# ADSP-2183xW_LPC register map
Vendor: Analog Devices; Series: ADSP-2183xW_LPC; File version: 3.0.3.517
CPU: 
Registers are 32-bit, read-write, reset 0x0 unless marked. A register's access mark holds for its fields unless they carry their own. Offsets are from the block's base; [hi:lo] are bit positions; {n}, {i} and the like mark numbered series.

## SPI1 — Serial Peripheral Interface
Base 0x3102F000
Same registers: SPI2 0x31030000
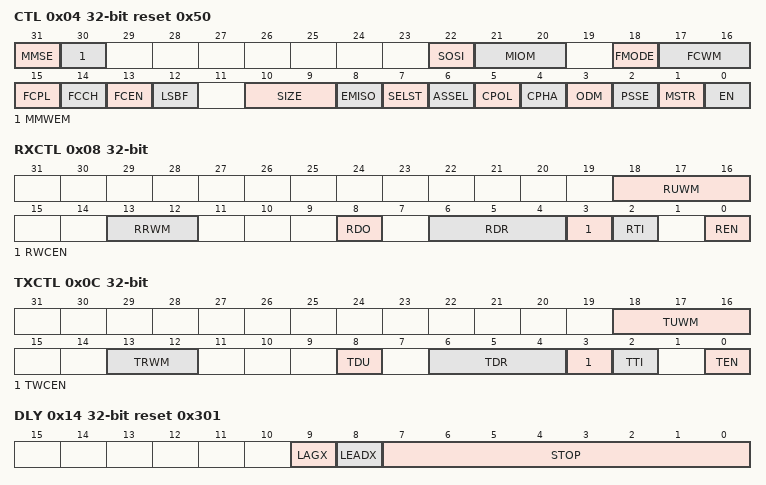
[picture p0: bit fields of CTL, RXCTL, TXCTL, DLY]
0x04 CTL reset 0x50 — Control Register
  [31] MMSE — Memory-Mapped SPI Enable
    0=MM_DIS (Hardware automated access of memory-mapped SPI memory disabled.); 1=MM_EN (Hardware-automated access of memory-mapped SPI memory enabled.)
  [30] MMWEM — Memory Mapped Write Error Mask
    0=WEM_UNMSK (Write error response returned upon write attempts to memory-mapped SPI memory); 1=WEM_MSK (Write error response masked (not returned) upon write attempts to memory-mapped SPI memory)
  [22] SOSI — Start on MOSI
    0=STMISO (Start on MISO (DIOM) or start on SPI_D3); 1=STMOSI (Start on MOSI)
  [21:20] MIOM — Multiple I/O Mode
    0=MIO_DIS (No MIOM (disabled)); 1=MIO_DUAL (DIOM operation); 2=MIO_QUAD (QIOM operation)
  [18] FMODE — Fast-Mode Enable
    0=FAST_DIS (Disable); 1=FAST_EN (Enable)
  [17:16] FCWM — Flow Control Watermark
    0=FIFO0 (TFIFO empty or RFIFO full); 1=FIFO1 (TFIFO 75 percent or more empty, or RFIFO 75 percent or more full); 2=FIFO2 (TFIFO 50 percent or more empty, or RFIFO 50 percent or more full)
  [15] FCPL — Flow Control Polarity
    0=FLOW_LO (Active-low RDY); 1=FLOW_HI (Active-high RDY)
  [14] FCCH — Flow Control Channel Selection
    0=FLOW_RX (Flow control on RX buffer); 1=FLOW_TX (Flow control on TX buffer)
  [13] FCEN — Flow Control Enable
    0=FLOW_DIS (Disable); 1=FLOW_EN (Enable)
  [12] LSBF — Least Significant Bit First
    0=MSB_FIRST (MSB sent/received first (big endian)); 1=LSB_FIRST (LSB sent/received first (little endian))
  [10:9] SIZE — Word Transfer Size
    0=8-bit word; 1=16-bit word; 2=32-bit word
  [8] EMISO — Enable MISO
    0=MISO_DIS (Disable); 1=MISO_EN (Enable)
  [7] SELST — Slave Select Polarity Between Transfers
    0=DEASSRT_SSEL (Deassert slave select (high)); 1=ASSRT_SSEL (Assert slave select (low))
  [6] ASSEL — Slave Select Pin Control
    0=SW_SSEL (Software slave select control); 1=HW_SSEL (Hardware slave select control)
  [5] CPOL — Clock Polarity
    0=SCKHI (Active-high SPI CLK); 1=SCKLO (Active-low SPI CLK)
  [4] CPHA — Clock Phase
    0=SCKMID (SPI CLK toggles from middle); 1=SCKBEG (SPI CLK toggles from start)
  [3] ODM — Open Drain Mode
    0=ODM_DIS (Disable); 1=ODM_EN (Enable)
  [2] PSSE — Protected Slave Select Enable
    0=PSSE_DIS (Disable); 1=PSSE_EN (Enable)
  [1] MSTR — Master/Slave
    0=SLAVE; 1=MASTER
  [0] EN — Enable
    0=DIS (Disable SPI module); 1=EN (Enable)
0x08 RXCTL — Receive Control Register
  [18:16] RUWM — Receive FIFO Urgent Watermark
    0=UWM_DIS (Disabled); 1=UWM_25 (25 percent full RFIFO); 2=UWM_50 (50 percent full RFIFO); 3=UWM_75 (75 percent full RFIFO); 4=UWM_FULL (Full RFIFO)
  [13:12] RRWM — Receive FIFO Regular Watermark
    0=RWM_0 (Empty RFIFO); 1=RWM_25 (RFIFO less than 25 percent full); 2=RWM_50 (RFIFO less than 50 percent full); 3=RWM_75 (RFIFO less than 75 percent full)
  [8] RDO — Receive Data Overrun
    0=DISCARD (Discard incoming data if SPI_RFIFO is full); 1=OVERWRITE (Overwrite old data if SPI_RFIFO is full)
  [6:4] RDR — Receive Data Request
    0=RDR_DIS (Disabled); 1=RDR_NE (Not empty RFIFO); 2=25 percent full RFIFO; 3=50 percent full RFIFO; 4=75 percent full RFIFO; 5=RDR_FULL (Full RFIFO)
  [3] RWCEN — Receive Word Counter Enable
    0=RWC_DIS (Disable); 1=RWC_EN (Enable)
  [2] RTI — Receive Transfer Initiate
    0=RTI_DIS (Disable); 1=RTI_EN (Enable)
  [0] REN — Receive Enable
    0=RX_DIS (Disable); 1=RX_EN (Enable)
0x0C TXCTL — Transmit Control Register
  [18:16] TUWM — FIFO Urgent Watermark
    0=UWM_DIS (Disabled); 1=UWM_25 (25 percent empty TFIFO); 2=UWM_50 (50 percent empty TFIFO); 3=UWM_75 (75 percent empty TFIFO); 4=UWM_EMPTY (Empty TFIFO)
  [13:12] TRWM — FIFO Regular Watermark
    0=RWM_FULL (Full TFIFO); 1=RWM_25 (TFIFO less than 25 percent empty); 2=RWM_50 (TFIFO less than 50 percent empty); 3=RWM_75 (TFIFO less than 75 percent empty)
  [8] TDU — Transmit Data Underrun
    0=LASTWD (Send last word when SPI_TFIFO is empty); 1=ZERO (Send zeros when SPI_TFIFO is empty)
  [6:4] TDR — Transmit Data Request
    0=TDR_DIS (Disabled); 1=TDR_NF (Not full TFIFO); 2=25 percent empty TFIFO; 3=50 percent empty TFIFO; 4=75 percent empty TFIFO; 5=TDR_EMPTY (Empty TFIFO)
  [3] TWCEN — Transmit Word Counter Enable
    0=TWC_DIS (Disable); 1=TWC_EN (Enable)
  [2] TTI — Transmit Transfer Initiate
    0=TTI_DIS (Disable); 1=TTI_EN (Enable)
  [0] TEN — Transmit Enable
    0=TX_DIS (Disable); 1=TX_EN (Enable)
0x10 CLK — Clock Rate Register
  [15:0] BAUD range 0x00000000..0x0000FFFF — Baud Rate
0x14 DLY reset 0x301 — Delay Register
  [9] LAGX — Extended SPI Clock Lag Control
  [8] LEADX — Extended SPI Clock Lead Control
  [7:0] STOP range 0x00000000..0x000000FF — Transfer Delay Time in Multiples of SPI Clock Period
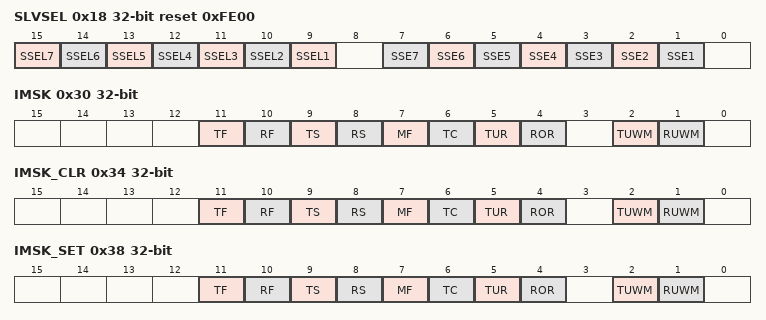
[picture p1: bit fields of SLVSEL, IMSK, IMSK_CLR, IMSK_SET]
0x18 SLVSEL reset 0xFE00 — Slave Select Register
  [n+8] SSEL{n} (n=1..7) — Slave Select {n} Output
    0=SSEL{n}_LO (Low); 1=SSEL{n}_HI (High)
  [n] SSE{n} (n=1..7) — Slave Select {n} Enable
    0=SSEL{n}_DIS (Disable); 1=SSEL{n}_EN (Enable)
0x1C RWC — Received Word Count Register
  [15:0] VALUE range 0x00000000..0x0000FFFF — Received Word Count
0x20 RWCR — Received Word Count Reload Register
  [15:0] VALUE range 0x00000000..0x0000FFFF — Received Word Count Reload
0x24 TWC — Transmitted Word Count Register
  [15:0] VALUE range 0x00000000..0x0000FFFF — Transmitted Word Count
0x28 TWCR — Transmitted Word Count Reload Register
  [15:0] VALUE range 0x00000000..0x0000FFFF — Transmitted Word Count Reload
0x30 IMSK — Interrupt Mask Register
  [11] TF ro — Transmit Finish
    0=TF_LO (Disable (mask) interrupt request); 1=TF_HI (Enable (unmask) interrupt request)
  [10] RF ro — Receive Finish
    0=RF_LO (Disable (mask) interrupt request); 1=RF_HI (Enable (unmask) interrupt request)
  [9] TS ro — Transmit Start
    0=TS_LO (Disable (mask) interrupt request); 1=TS_HI (Enable (unmask) interrupt request)
  [8] RS ro — Receive Start
    0=RS_LO (Disable (mask) interrupt request); 1=RS_HI (Enable (unmask) interrupt request)
  [7] MF ro — Mode Fault
    0=MF_LO (Disable (mask) interrupt request); 1=MF_HI (Enable (unmask) interrupt request)
  [6] TC ro — Transmit Collision
    0=TC_LO (Disable (mask) interrupt request); 1=TC_HI (Enable (unmask) interrupt request)
  [5] TUR ro — Transmit Underrun
    0=TUR_LO (Disable (mask) interrupt request); 1=TUR_HI (Enable (unmask) interrupt request)
  [4] ROR ro — Receive Overrun
    0=ROR_LO (Disable (mask) interrupt request); 1=ROR_HI (Enable (unmask) interrupt request)
  [2] TUWM ro — Transmit Urgent Watermark
    0=TUWM_LO (Disable (mask) interrupt request); 1=TUWM_HI (Enable (unmask) interrupt request)
  [1] RUWM ro — Receive Urgent Watermark
    0=RUWM_LO (Disable (mask) interrupt request); 1=RUWM_HI (Enable (unmask) interrupt request)
0x34 IMSK_CLR — Interrupt Mask Clear Register
  [11] TF — Clear Transmit Finish
  [10] RF — Clear Receive Finish
  [9] TS — Clear Transmit Start
  [8] RS — Clear Receive Start
  [7] MF — Clear Mode Fault
  [6] TC — Clear Transmit Collision
  [5] TUR — Clear Transmit Underrun
  [4] ROR — Clear Receive Overrun
  [2] TUWM — Clear Transmit Urgent Watermark
  [1] RUWM — Clear Receive Urgent Watermark
0x38 IMSK_SET — Interrupt Mask Set Register
  [11] TF — Set Transmit Finish
  [10] RF — Set Receive Finish
  [9] TS — Set Transmit Start
  [8] RS — Set Receive Start
  [7] MF — Set Mode Fault
  [6] TC — Set Transmit Collision
  [5] TUR — Set Transmit Underrun
  [4] ROR — Set Receive Overrun
  [2] TUWM — Set Transmit Urgent Watermark
  [1] RUWM — Set Receive Urgent Watermark
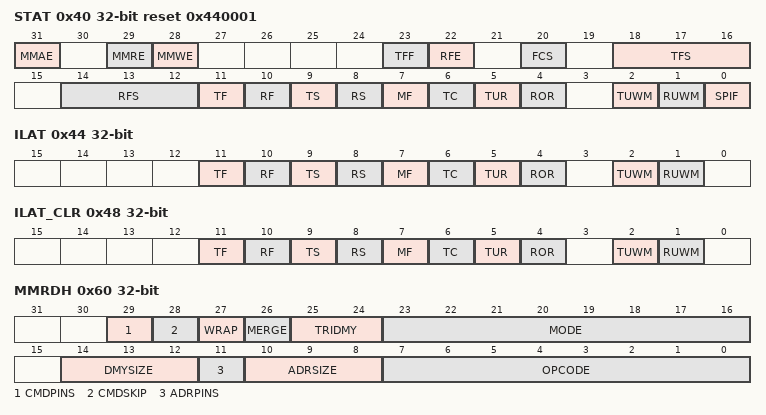
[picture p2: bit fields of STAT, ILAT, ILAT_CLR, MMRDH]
0x40 STAT reset 0x440001 — Status Register
  [31] MMAE range 0x00000000..0x00000001 — Memory Mapped Access Error
  [29] MMRE range 0x00000000..0x00000001 — Memory Mapped Read Error
  [28] MMWE range 0x00000000..0x00000001 — Memory Mapped Write Error
  [23] TFF ro — SPI_TFIFO Full
    0=TFIFO_NF (Not full Tx FIFO); 1=TFIFO_F (Full Tx FIFO)
  [22] RFE ro — SPI_RFIFO Empty
    0=RFIFO_NE (Rx FIFO not empty); 1=RFIFO_E (Rx FIFO empty)
  [20] FCS ro — Flow Control Stall Indication
    0=STALL (No Stall (RDY pin asserted)); 1=NOSTALL (Stall (RDY pin deasserted))
  [18:16] TFS ro — SPI_TFIFO Status
    0=TFIFO_FULL (Full TFIFO); 1=TFIFO_25 (25 percent empty TFIFO); 2=TFIFO_50 (50 percent empty TFIFO); 3=TFIFO_75 (75 percent empty TFIFO); 4=TFIFO_EMPTY (Empty TFIFO)
  [14:12] RFS ro — SPI_RFIFO Status
    0=RFIFO_EMPTY (Empty RFIFO); 1=RFIFO_25 (25 percent full RFIFO); 2=RFIFO_50 (50 percent full RFIFO); 3=RFIFO_75 (75 percent full RFIFO); 4=RFIFO_FULL (Full RFIFO)
  [11] TF — Transmit Finish Indication
    0=TF_LO (No status); 1=TF_HI (Transmit finish detected)
  [10] RF — Receive Finish Indication
    0=RF_LO (No status); 1=RF_HI (Receive finish detected)
  [9] TS — Transmit Start
    0=TS_LO (No status); 1=TS_HI (Transmit start detected)
  [8] RS — Receive Start
    0=RS_LO (No status); 1=RS_HI (Receive start detected)
  [7] MF — Mode Fault Indication
    0=MF_LO (No status); 1=MF_HI (Mode fault occurred)
  [6] TC — Transmit Collision Indication
    0=TC_LO (No status); 1=TC_HI (Transmit collision occurred)
  [5] TUR — Transmit Underrun Indication
    0=TUR_LO (No status); 1=TUR_HI (Transmit underrun occurred)
  [4] ROR — Receive Overrun Indication
    0=ROR_LO (No status); 1=ROR_HI (Receive overrun occurred)
  [2] TUWM ro — Transmit Urgent Watermark Breached
    0=TUWM_LO (Tx regular watermark reached); 1=TUWM_HI (Tx urgent watermark breached)
  [1] RUWM ro — Receive Urgent Watermark Breached
    0=RUWM_LO (Rx regular watermark reached); 1=RUWM_HI (Rx urgent watermark breached)
  [0] SPIF ro — SPI Finished
    0=SPIF_LO (No status); 1=SPIF_HI (Completed single word transfer)
0x44 ILAT — Masked Interrupt Condition Register
  [11] TF ro — Transmit Finish Interrupt Latch
    0=TF_LO (No interrupt request); 1=TF_HI (Latched interrupt request)
  [10] RF ro — Receive Finish Interrupt Latch
    0=RF_LO (No interrupt request); 1=RF_HI (Latched interrupt request)
  [9] TS ro — Transmit Start Interrupt Latch
    0=TS_LO (No interrupt request); 1=TS_HI (Latched interrupt request)
  [8] RS ro — Receive Start Interrupt Latch
    0=RS_LO (No interrupt request); 1=RS_HI (Latched interrupt request)
  [7] MF ro — Mode Fault Interrupt Latch
    0=MF_LO (No interrupt request); 1=MF_HI (Latched interrupt request)
  [6] TC ro — Transmit Collision Interrupt Latch
    0=TC_LO (No interrupt request); 1=TC_HI (Latched interrupt request)
  [5] TUR ro — Transmit Underrun Interrupt Latch
    0=TUR_LO (No interrupt request); 1=TUR_HI (Latched interrupt request)
  [4] ROR ro — Receive Overrun Interrupt Latch
    0=ROR_LO (No interrupt request); 1=ROR_HI (Latched interrupt request)
  [2] TUWM ro — Transmit Urgent Watermark Interrupt Latch
    0=TUWM_LO (No interrupt request); 1=TUWM_HI (Latched interrupt request)
  [1] RUWM ro — Receive Urgent Watermark Interrupt Latch
    0=RUWM_LO (No interrupt request); 1=RUWM_HI (Latched interrupt request)
0x48 ILAT_CLR — Masked Interrupt Clear Register
  [11] TF — Clear Transmit Finish
  [10] RF — Clear Receive Finish
  [9] TS — Clear Transmit Start
  [8] RS — Clear Receive Start
  [7] MF — Clear Mode Fault
  [6] TC — Clear Transmit Collision
  [5] TUR — Clear Transmit Underrun
  [4] ROR — Clear Receive Overrun
  [2] TUWM ro — Clear Transmit Urgent Watermark
  [1] RUWM ro — Clear Receive Urgent Watermark
0x50 RFIFO — Receive FIFO Data Register
  [31:0] DATA ro — Receive FIFO Data
0x58 TFIFO — Transmit FIFO Data Register
  [31:0] DATA range 0x00000000..0xFFFFFFFF — Transmit FIFO Data
0x60 MMRDH — Memory Mapped Read Header
  [29] CMDPINS — Pins Used for Command
  [28] CMDSKIP — Command Skip Enable
  [27] WRAP — SPI Memory Wrap Indicator
  [26] MERGE range 0x00000000..0x00000001 — Merge Enable
  [25:24] TRIDMY — Tristate Dummy Timing
  [23:16] MODE range 0x00000000..0x000000FF
  [14:12] DMYSIZE — Bytes of Dummy/Mode
  [11] ADRPINS — Pins Used for Address
  [10:8] ADRSIZE — Bytes of Read Address
  [7:0] OPCODE range 0x00000000..0x000000FF — Read Opcode
0x64 MMTOP — SPI Memory Top Address
  [31:0] TOPADR range 0x00000000..0xFFFFFFFF
